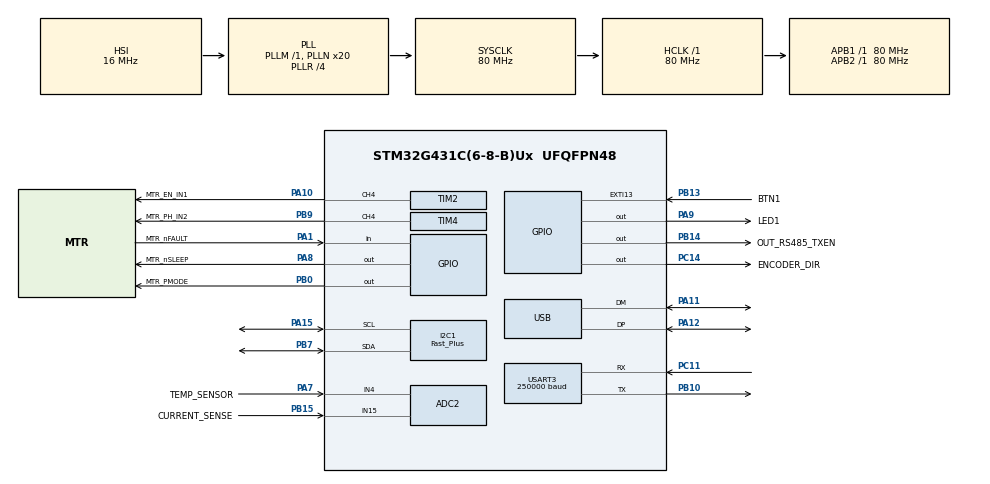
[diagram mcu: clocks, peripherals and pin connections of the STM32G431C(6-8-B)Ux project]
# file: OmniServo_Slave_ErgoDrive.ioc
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ADC2.Channel-1\#ChannelRegularConversion=ADC_CHANNEL_15
ADC2.Channel-2\#ChannelRegularConversion=ADC_CHANNEL_4
ADC2.ClockPrescaler=ADC_CLOCK_ASYNC_DIV256
ADC2.ContinuousConvMode=DISABLE
ADC2.DMAContinuousRequests=DISABLE
ADC2.DiscontinuousConvMode=DISABLE
ADC2.EOCSelection=ADC_EOC_SEQ_CONV
ADC2.NbrOfConversion=2
ADC2.NbrOfConversionFlag=1
ADC2.OffsetNumber-1\#ChannelRegularConversion=ADC_OFFSET_NONE
ADC2.OffsetNumber-2\#ChannelRegularConversion=ADC_OFFSET_NONE
ADC2.Rank-1\#ChannelRegularConversion=1
ADC2.Rank-2\#ChannelRegularConversion=2
ADC2.SamplingTime-1\#ChannelRegularConversion=ADC_SAMPLETIME_92CYCLES_5
ADC2.SamplingTime-2\#ChannelRegularConversion=ADC_SAMPLETIME_92CYCLES_5
Dma.ADC2.4.Direction=DMA_PERIPH_TO_MEMORY
Dma.ADC2.4.EventEnable=DISABLE
Dma.ADC2.4.Instance=DMA1_Channel5
Dma.ADC2.4.MemDataAlignment=DMA_MDATAALIGN_HALFWORD
Dma.ADC2.4.MemInc=DMA_MINC_ENABLE
Dma.ADC2.4.Mode=DMA_NORMAL
Dma.ADC2.4.PeriphDataAlignment=DMA_PDATAALIGN_HALFWORD
Dma.ADC2.4.PeriphInc=DMA_PINC_DISABLE
Dma.ADC2.4.Polarity=HAL_DMAMUX_REQ_GEN_RISING
Dma.ADC2.4.Priority=DMA_PRIORITY_LOW
Dma.ADC2.4.RequestNumber=1
Dma.ADC2.4.SignalID=NONE
Dma.ADC2.4.SyncEnable=DISABLE
Dma.ADC2.4.SyncPolarity=HAL_DMAMUX_SYNC_NO_EVENT
Dma.ADC2.4.SyncRequestNumber=1
Dma.ADC2.4.SyncSignalID=NONE
Dma.I2C1_RX.2.Direction=DMA_PERIPH_TO_MEMORY
Dma.I2C1_RX.2.EventEnable=DISABLE
Dma.I2C1_RX.2.Instance=DMA1_Channel3
Dma.I2C1_RX.2.MemDataAlignment=DMA_MDATAALIGN_BYTE
Dma.I2C1_RX.2.MemInc=DMA_MINC_ENABLE
Dma.I2C1_RX.2.Mode=DMA_NORMAL
Dma.I2C1_RX.2.PeriphDataAlignment=DMA_PDATAALIGN_BYTE
Dma.I2C1_RX.2.PeriphInc=DMA_PINC_DISABLE
Dma.I2C1_RX.2.Polarity=HAL_DMAMUX_REQ_GEN_RISING
Dma.I2C1_RX.2.Priority=DMA_PRIORITY_LOW
Dma.I2C1_RX.2.RequestNumber=1
Dma.I2C1_RX.2.SignalID=NONE
Dma.I2C1_RX.2.SyncEnable=DISABLE
Dma.I2C1_RX.2.SyncPolarity=HAL_DMAMUX_SYNC_NO_EVENT
Dma.I2C1_RX.2.SyncRequestNumber=1
Dma.I2C1_RX.2.SyncSignalID=NONE
Dma.I2C1_TX.3.Direction=DMA_MEMORY_TO_PERIPH
Dma.I2C1_TX.3.EventEnable=DISABLE
Dma.I2C1_TX.3.Instance=DMA1_Channel4
Dma.I2C1_TX.3.MemDataAlignment=DMA_MDATAALIGN_BYTE
Dma.I2C1_TX.3.MemInc=DMA_MINC_ENABLE
Dma.I2C1_TX.3.Mode=DMA_NORMAL
Dma.I2C1_TX.3.PeriphDataAlignment=DMA_PDATAALIGN_BYTE
Dma.I2C1_TX.3.PeriphInc=DMA_PINC_DISABLE
Dma.I2C1_TX.3.Polarity=HAL_DMAMUX_REQ_GEN_RISING
Dma.I2C1_TX.3.Priority=DMA_PRIORITY_LOW
Dma.I2C1_TX.3.RequestNumber=1
Dma.I2C1_TX.3.SignalID=NONE
Dma.I2C1_TX.3.SyncEnable=DISABLE
Dma.I2C1_TX.3.SyncPolarity=HAL_DMAMUX_SYNC_NO_EVENT
Dma.I2C1_TX.3.SyncRequestNumber=1
Dma.I2C1_TX.3.SyncSignalID=NONE
Dma.Request0=USART3_RX
Dma.Request1=USART3_TX
Dma.Request2=I2C1_RX
Dma.Request3=I2C1_TX
Dma.Request4=ADC2
Dma.USART3_RX.0.Direction=DMA_PERIPH_TO_MEMORY
Dma.USART3_RX.0.EventEnable=DISABLE
Dma.USART3_RX.0.Instance=DMA1_Channel1
Dma.USART3_RX.0.MemDataAlignment=DMA_MDATAALIGN_BYTE
Dma.USART3_RX.0.MemInc=DMA_MINC_ENABLE
Dma.USART3_RX.0.Mode=DMA_NORMAL
Dma.USART3_RX.0.PeriphDataAlignment=DMA_PDATAALIGN_BYTE
Dma.USART3_RX.0.PeriphInc=DMA_PINC_DISABLE
Dma.USART3_RX.0.Polarity=HAL_DMAMUX_REQ_GEN_RISING
Dma.USART3_RX.0.Priority=DMA_PRIORITY_HIGH
Dma.USART3_RX.0.RequestNumber=1
Dma.USART3_RX.0.SignalID=NONE
Dma.USART3_RX.0.SyncEnable=DISABLE
Dma.USART3_RX.0.SyncPolarity=HAL_DMAMUX_SYNC_NO_EVENT
Dma.USART3_RX.0.SyncRequestNumber=1
Dma.USART3_RX.0.SyncSignalID=NONE
Dma.USART3_TX.1.Direction=DMA_MEMORY_TO_PERIPH
Dma.USART3_TX.1.EventEnable=DISABLE
Dma.USART3_TX.1.Instance=DMA1_Channel2
Dma.USART3_TX.1.MemDataAlignment=DMA_MDATAALIGN_BYTE
Dma.USART3_TX.1.MemInc=DMA_MINC_ENABLE
Dma.USART3_TX.1.Mode=DMA_NORMAL
Dma.USART3_TX.1.PeriphDataAlignment=DMA_PDATAALIGN_BYTE
Dma.USART3_TX.1.PeriphInc=DMA_PINC_DISABLE
Dma.USART3_TX.1.Polarity=HAL_DMAMUX_REQ_GEN_RISING
Dma.USART3_TX.1.Priority=DMA_PRIORITY_HIGH
Dma.USART3_TX.1.RequestNumber=1
Dma.USART3_TX.1.SignalID=NONE
Dma.USART3_TX.1.SyncEnable=DISABLE
Dma.USART3_TX.1.SyncPolarity=HAL_DMAMUX_SYNC_NO_EVENT
Dma.USART3_TX.1.SyncRequestNumber=1
Dma.USART3_TX.1.SyncSignalID=NONE
I2C1.I2C_Speed_Mode=I2C_Fast_Plus
I2C1.Timing=0x00B10E24
Mcu.Family=STM32G4
Mcu.Name=STM32G431C(6-8-B)Ux
Mcu.Package=UFQFPN48
NVIC.ADC1_2_IRQn=true\:5\:0\:true\:false\:true\:true\:true\:true
NVIC.DMA1_Channel1_IRQn=true\:1\:0\:true\:false\:true\:false\:true\:true
NVIC.DMA1_Channel2_IRQn=true\:1\:0\:true\:false\:true\:false\:true\:true
NVIC.DMA1_Channel3_IRQn=true\:4\:0\:true\:false\:true\:false\:true\:true
NVIC.DMA1_Channel4_IRQn=true\:4\:0\:true\:false\:true\:false\:true\:true
NVIC.DMA1_Channel5_IRQn=true\:5\:0\:true\:false\:true\:false\:true\:true
NVIC.EXTI15_10_IRQn=true\:0\:0\:false\:false\:true\:true\:true\:true
NVIC.FLASH_IRQn=true\:1\:0\:true\:false\:true\:true\:true\:true
NVIC.I2C1_ER_IRQn=true\:0\:0\:false\:false\:true\:true\:true\:true
NVIC.I2C1_EV_IRQn=true\:4\:0\:true\:false\:true\:true\:true\:true
NVIC.PriorityGroup=NVIC_PRIORITYGROUP_4
NVIC.TIM3_IRQn=true\:2\:0\:true\:false\:true\:true\:true\:true
NVIC.TIM6_DAC_IRQn=true\:0\:0\:false\:false\:true\:true\:true\:true
NVIC.USART3_IRQn=true\:3\:0\:true\:false\:true\:true\:true\:true
NVIC.USB_LP_IRQn=true\:14\:0\:true\:false\:true\:false\:true\:true
PA1.GPIO_Label=MTR_nFAULT
PA1.GPIO_PuPd=GPIO_PULLUP
PA1.Signal=GPIO_Input
PA10.GPIO_Label=MTR_EN_IN1
PA10.GPIO_PuPd=GPIO_PULLUP
PA10.Signal=S_TIM2_CH4
PA11.Mode=Device
PA11.Signal=USB_DM
PA12.Mode=Device
PA12.Signal=USB_DP
PA15.GPIO_Pu=GPIO_PULLUP
PA15.Mode=I2C
PA15.Signal=I2C1_SCL
PA7.GPIO_Label=TEMP_SENSOR
PA7.Mode=IN4-Single-Ended
PA7.Signal=ADC2_IN4
PA8.GPIO_Label=MTR_nSLEEP
PA8.GPIO_PuPd=GPIO_PULLUP
PA8.Signal=GPIO_Output
PA9.GPIO_Label=LED1
PA9.PinState=GPIO_PIN_SET
PA9.Signal=GPIO_Output
PB0.GPIO_Label=MTR_PMODE
PB0.GPIO_PuPd=GPIO_PULLUP
PB0.Signal=GPIO_Output
PB10.GPIO_PuPd=GPIO_PULLUP
PB10.GPIO_Speed=GPIO_SPEED_FREQ_VERY_HIGH
PB10.Mode=Asynchronous
PB10.Signal=USART3_TX
PB13.GPIO_Label=BTN1
PB13.GPIO_ModeDefaultEXTI=GPIO_MODE_IT_FALLING
PB13.GPIO_PuPd=GPIO_PULLUP
PB13.Signal=GPXTI13
PB14.GPIO_Label=OUT_RS485_TXEN
PB14.GPIO_PuPd=GPIO_PULLUP
PB14.GPIO_Speed=GPIO_SPEED_FREQ_HIGH
PB14.Signal=GPIO_Output
PB15.GPIO_Label=CURRENT_SENSE
PB15.Mode=IN15-Single-Ended
PB15.Signal=ADC2_IN15
PB7.GPIO_Pu=GPIO_PULLUP
PB7.Mode=I2C
PB7.Signal=I2C1_SDA
PB9.GPIO_Label=MTR_PH_IN2
PB9.Signal=S_TIM4_CH4
PC11.GPIO_PuPd=GPIO_PULLUP
PC11.GPIO_Speed=GPIO_SPEED_FREQ_VERY_HIGH
PC11.Mode=Asynchronous
PC11.Signal=USART3_RX
PC14-OSC32_IN.GPIO_Label=ENCODER_DIR
PC14-OSC32_IN.GPIO_PuPd=GPIO_PULLUP
PC14-OSC32_IN.PinState=GPIO_PIN_RESET
PC14-OSC32_IN.Signal=GPIO_Output
PF0-OSC_IN.Mode=HSE-External-Oscillator
PF0-OSC_IN.Signal=RCC_OSC_IN
PF1-OSC_OUT.Mode=HSE-External-Oscillator
PF1-OSC_OUT.Signal=RCC_OSC_OUT
ProjectManager.HeapSize=0x400
ProjectManager.StackSize=0x800
ProjectManager.TargetToolchain=STM32CubeIDE
RCC.ADC12Freq_Value=80000000
RCC.AHBFreq_Value=80000000
RCC.APB1Freq_Value=80000000
RCC.APB1TimFreq_Value=80000000
RCC.APB2Freq_Value=80000000
RCC.APB2TimFreq_Value=80000000
RCC.CK48CLockSelection=RCC_USBCLKSOURCE_HSI48
RCC.CortexFreq_Value=80000000
RCC.EXTERNAL_CLOCK_VALUE=12288000
RCC.HCLKFreq_Value=80000000
RCC.HSE_VALUE=8000000
RCC.HSI48_VALUE=48000000
RCC.HSI_VALUE=16000000
RCC.LSE_VALUE=32768
RCC.PLLN=20
RCC.PLLSourceVirtual=RCC_PLLSOURCE_HSE
RCC.SYSCLKFreq_VALUE=80000000
RCC.SYSCLKSource=RCC_SYSCLKSOURCE_PLLCLK
RCC.USART3CLockSelection=RCC_USART3CLKSOURCE_SYSCLK
RCC.USBFreq_Value=48000000
RCC.VCOOutputFreq_Value=160000000
SH.S_TIM2_CH4.0=TIM2_CH4,PWM Generation4 CH4
SH.S_TIM4_CH4.0=TIM4_CH4,PWM Generation4 CH4
TIM2.Channel-PWM\ Generation4\ CH4=TIM_CHANNEL_4
TIM2.PeriodNoDither=2000-1
TIM3.PeriodNoDither=10000-1
TIM3.Prescaler=8-1
TIM4.Channel-PWM\ Generation4\ CH4=TIM_CHANNEL_4
TIM4.PeriodNoDither=2000-1
TIM6.PeriodNoDither=100-1
TIM6.Prescaler=80-1
USART3.AutoBaudRateEnableParam=UART_ADVFEATURE_AUTOBAUDRATE_DISABLE
USART3.BaudRate=250000
USART3.OneBitSampling=UART_ONE_BIT_SAMPLE_DISABLE
USART3.OverSampling=UART_OVERSAMPLING_16
USART3.VirtualMode-Asynchronous=VM_ASYNC
USB_DEVICE.CLASS_NAME_FS=CDC
USB_DEVICE.VirtualMode=Cdc
USB_DEVICE.VirtualModeFS=Cdc_FS
VP_CRC_VS_CRC.Mode=CRC_Activate
VP_SYS_VS_DBSignals.Mode=DisableDeadBatterySignals
VP_SYS_V_VREFBUF.Mode=ExternalMode
VP_TIM2_VS_ClockSourceINT.Mode=Internal
VP_TIM3_VS_ClockSourceINT.Mode=Internal
VP_TIM4_VS_ClockSourceINT.Mode=Internal
VP_TIM6_VS_ClockSourceINT.Mode=Enable_Timer
VP_USB_DEVICE_VS_USB_DEVICE_CDC_FS.Mode=CDC_FS
board=custom

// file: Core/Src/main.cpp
/* USER CODE BEGIN Header */
/**
  ******************************************************************************
  * @file           : main.c
  * @brief          : Main program body
  ******************************************************************************
  * @attention
  *
  * Copyright (c) 2024 STMicroelectronics.
  * All rights reserved.
  *
  * This software is licensed under terms that can be found in the LICENSE file
  * in the root directory of this software component.
  * If no LICENSE file comes with this software, it is provided AS-IS.
  *
  ******************************************************************************
  */
/* USER CODE END Header */
#include "main.h"
#include "adc.h"
#include "crc.h"
#include "dma.h"
#include "i2c.h"
#include "tim.h"
#include "usart.h"
#include "usb_device.h"
#include "gpio.h"

/* USER CODE BEGIN Includes */
#include "mainApp.h"
/* USER CODE END Includes */

void SystemClock_Config(void);

int main(void)
{

  /* MCU Configuration--------------------------------------------------------*/

  /* Reset of all peripherals, Initializes the Flash interface and the Systick. */
  HAL_Init();

  /* Configure the system clock */
  SystemClock_Config();

  /* Initialize all configured peripherals */
  MX_GPIO_Init();
  MX_DMA_Init();
  MX_USART3_UART_Init();
  MX_TIM2_Init();
  MX_I2C1_Init();
  MX_TIM3_Init();
  MX_ADC2_Init();
  MX_USB_Device_Init();
  MX_CRC_Init();
  MX_TIM4_Init();
  MX_TIM6_Init();

  /* USER CODE BEGIN 2 */
  setup();
  /* USER CODE END 2 */

  /* Infinite loop */
  /* USER CODE BEGIN WHILE */
  while (1)
  {
	  loop();
    /* USER CODE END WHILE */

  }
}

void SystemClock_Config(void)
{
  RCC_OscInitTypeDef RCC_OscInitStruct = {0};
  RCC_ClkInitTypeDef RCC_ClkInitStruct = {0};

  /** Configure the main internal regulator output voltage
  */
  HAL_PWREx_ControlVoltageScaling(PWR_REGULATOR_VOLTAGE_SCALE1);

  /** Initializes the RCC Oscillators according to the specified parameters
  * in the RCC_OscInitTypeDef structure.
  */
  RCC_OscInitStruct.OscillatorType = RCC_OSCILLATORTYPE_HSI|RCC_OSCILLATORTYPE_HSI48;
  RCC_OscInitStruct.HSIState = RCC_HSI_ON;
  RCC_OscInitStruct.HSICalibrationValue = RCC_HSICALIBRATION_DEFAULT;
  RCC_OscInitStruct.HSI48State = RCC_HSI48_ON;
  RCC_OscInitStruct.PLL.PLLState = RCC_PLL_ON;
  RCC_OscInitStruct.PLL.PLLSource = RCC_PLLSOURCE_HSI;
  RCC_OscInitStruct.PLL.PLLM = RCC_PLLM_DIV1;
  RCC_OscInitStruct.PLL.PLLN = 20;
  RCC_OscInitStruct.PLL.PLLP = RCC_PLLP_DIV2;
  RCC_OscInitStruct.PLL.PLLQ = RCC_PLLQ_DIV4;
  RCC_OscInitStruct.PLL.PLLR = RCC_PLLR_DIV4;
  if (HAL_RCC_OscConfig(&RCC_OscInitStruct) != HAL_OK)
  {
    Error_Handler();
  }

  /** Initializes the CPU, AHB and APB buses clocks
  */
  RCC_ClkInitStruct.ClockType = RCC_CLOCKTYPE_HCLK|RCC_CLOCKTYPE_SYSCLK
                              |RCC_CLOCKTYPE_PCLK1|RCC_CLOCKTYPE_PCLK2;
  RCC_ClkInitStruct.SYSCLKSource = RCC_SYSCLKSOURCE_PLLCLK;
  RCC_ClkInitStruct.AHBCLKDivider = RCC_SYSCLK_DIV1;
  RCC_ClkInitStruct.APB1CLKDivider = RCC_HCLK_DIV1;
  RCC_ClkInitStruct.APB2CLKDivider = RCC_HCLK_DIV1;

  if (HAL_RCC_ClockConfig(&RCC_ClkInitStruct, FLASH_LATENCY_2) != HAL_OK)
  {
    Error_Handler();
  }
}

void Error_Handler(void)
{
  __disable_irq();
  while (1)
  {
  }
}
